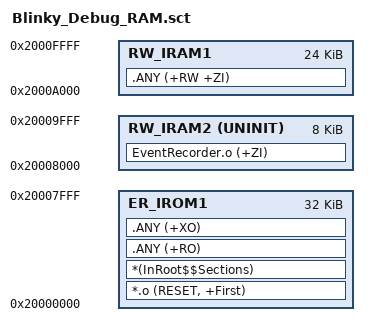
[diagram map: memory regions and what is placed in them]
; ***********************************************************************
; *** Scatter-Loading Description File generated by uv2csolution ***
; ***********************************************************************

LR_IROM1 0x20000000 0x00008000 {    ; load region size_region
  ER_IROM1 0x20000000 0x00008000 {  ; load address = execution address
   *.o (RESET, +First)
   *(InRoot$$Sections)
   .ANY (+RO)
   .ANY (+XO)
  }
  RW_IRAM1 0x2000A000 0x00006000 {  ; RW data
   .ANY (+RW +ZI)
  }
  RW_IRAM2 0x20008000 UNINIT 0x00002000 {
    EventRecorder.o (+ZI)
  }
}

